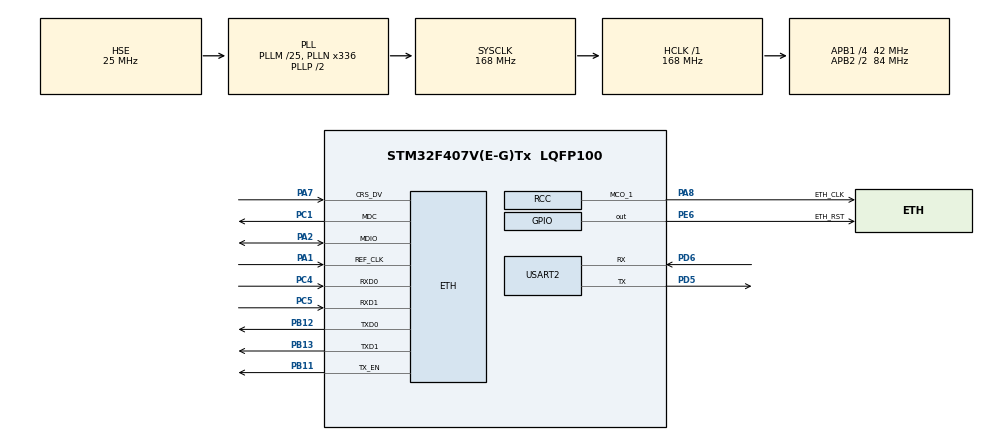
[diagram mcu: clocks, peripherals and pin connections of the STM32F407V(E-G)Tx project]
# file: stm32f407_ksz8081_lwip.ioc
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ETH.MACAddr=00\:80\:E1\:00\:00\:01
ETH.MediaInterface=HAL_ETH_RMII_MODE
LWIP.BSP.number=1
LWIP.CHECKSUM_BY_HARDWARE=0
LWIP.CHECKSUM_CHECK_IP=1
LWIP.CHECKSUM_CHECK_TCP=1
LWIP.CHECKSUM_CHECK_UDP=1
LWIP.CHECKSUM_GEN_ICMP=0
LWIP.CHECKSUM_GEN_IP=1
LWIP.CHECKSUM_GEN_TCP=1
LWIP.CHECKSUM_GEN_UDP=1
LWIP.IP_ADDRESS=192.168.100.118
LWIP.LWIP_DHCP=0
LWIP.NETMASK_ADDRESS=255.255.255.000
LWIP.Version=v2.1.2_Cube
LWIP0.BSP.STBoard=false
LWIP0.BSP.api=BSP_COMPONENT_DRIVER
LWIP0.BSP.component=LAN8742
LWIP0.BSP.i2caddr=0
LWIP0.BSP.instance=LAN8742
LWIP0.BSP.name=Driver_PHY
LWIP0.BSP.semaphore=S_LAN8742
LWIP0.BSP.solution=LAN8742
Mcu.Family=STM32F4
Mcu.Name=STM32F407V(E-G)Tx
Mcu.Package=LQFP100
NVIC.PriorityGroup=NVIC_PRIORITYGROUP_4
NVIC.USART2_IRQn=true\:0\:0\:false\:false\:true\:true\:true\:true
PA1.Mode=RMII
PA1.Signal=ETH_REF_CLK
PA2.Mode=RMII
PA2.Signal=ETH_MDIO
PA7.Mode=RMII
PA7.Signal=ETH_CRS_DV
PA8.GPIO_Label=ETH_CLK
PA8.Mode=Clock-out-1
PA8.Signal=RCC_MCO_1
PB11.Mode=RMII
PB11.Signal=ETH_TX_EN
PB12.Mode=RMII
PB12.Signal=ETH_TXD0
PB13.Mode=RMII
PB13.Signal=ETH_TXD1
PC1.Mode=RMII
PC1.Signal=ETH_MDC
PC4.Mode=RMII
PC4.Signal=ETH_RXD0
PC5.Mode=RMII
PC5.Signal=ETH_RXD1
PD5.Mode=Asynchronous
PD5.Signal=USART2_TX
PD6.Mode=Asynchronous
PD6.Signal=USART2_RX
PE6.GPIO_Label=ETH_RST
PE6.Signal=GPIO_Output
PH0-OSC_IN.Mode=HSE-External-Oscillator
PH0-OSC_IN.Signal=RCC_OSC_IN
PH1-OSC_OUT.Mode=HSE-External-Oscillator
PH1-OSC_OUT.Signal=RCC_OSC_OUT
ProjectManager.HeapSize=0x200
ProjectManager.StackSize=0x400
ProjectManager.TargetToolchain=STM32CubeIDE
RCC.48MHZClocksFreq_Value=84000000
RCC.AHBFreq_Value=168000000
RCC.APB1CLKDivider=RCC_HCLK_DIV4
RCC.APB1Freq_Value=42000000
RCC.APB1TimFreq_Value=84000000
RCC.APB2CLKDivider=RCC_HCLK_DIV2
RCC.APB2Freq_Value=84000000
RCC.APB2TimFreq_Value=168000000
RCC.CortexFreq_Value=168000000
RCC.HCLKFreq_Value=168000000
RCC.HSE_VALUE=25000000
RCC.HSI_VALUE=16000000
RCC.LSE_VALUE=32768
RCC.PLLM=25
RCC.PLLN=336
RCC.PLLSourceVirtual=RCC_PLLSOURCE_HSE
RCC.RCC_MCO1Source=RCC_MCO1SOURCE_HSE
RCC.SYSCLKFreq_VALUE=168000000
RCC.SYSCLKSource=RCC_SYSCLKSOURCE_PLLCLK
RCC.VCOOutputFreq_Value=336000000
USART2.VirtualMode=VM_ASYNC
VP_LWIP_VS_Enabled.Mode=Enabled
board=custom

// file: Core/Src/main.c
/* USER CODE BEGIN Header */
/**
  ******************************************************************************
  * @file           : main.c
  * @brief          : Main program body
  ******************************************************************************
  * @attention
  *
  * Copyright (c) 2022 STMicroelectronics.
  * All rights reserved.
  *
  * This software is licensed under terms that can be found in the LICENSE file
  * in the root directory of this software component.
  * If no LICENSE file comes with this software, it is provided AS-IS.
  *
  ******************************************************************************
  */
/* USER CODE END Header */
#include "main.h"
#include "lwip.h"

/* USER CODE BEGIN PTD */
#ifdef __GNUC__
/* With GCC/RAISONANCE, small printf (option LD Linker->Libraries->Small printf
 set to 'Yes') calls __io_putchar() */
#define PUTCHAR_PROTOTYPE int __io_putchar(int ch)
#else
#define PUTCHAR_PROTOTYPE int fputc(int ch, FILE *f)
#endif /* __GNUC__ */

/* USER CODE END PTD */

 UART_HandleTypeDef huart2;

void SystemClock_Config(void);
static void MX_GPIO_Init(void);
static void MX_USART2_UART_Init(void);

int main(void)
{

  /* MCU Configuration--------------------------------------------------------*/

  /* Reset of all peripherals, Initializes the Flash interface and the Systick. */
  HAL_Init();

  /* Configure the system clock */
  SystemClock_Config();

  /* Initialize all configured peripherals */
  MX_GPIO_Init();
  MX_USART2_UART_Init();
  MX_LWIP_Init();

  /* Infinite loop */
  while (1)
  {

    /* USER CODE BEGIN 3 */
	  MX_LWIP_Process();
  }
  /* USER CODE END 3 */
}

void SystemClock_Config(void)
{
  RCC_OscInitTypeDef RCC_OscInitStruct = {0};
  RCC_ClkInitTypeDef RCC_ClkInitStruct = {0};

  /** Configure the main internal regulator output voltage
  */
  __HAL_RCC_PWR_CLK_ENABLE();
  __HAL_PWR_VOLTAGESCALING_CONFIG(PWR_REGULATOR_VOLTAGE_SCALE1);

  /** Initializes the RCC Oscillators according to the specified parameters
  * in the RCC_OscInitTypeDef structure.
  */
  RCC_OscInitStruct.OscillatorType = RCC_OSCILLATORTYPE_HSE;
  RCC_OscInitStruct.HSEState = RCC_HSE_ON;
  RCC_OscInitStruct.PLL.PLLState = RCC_PLL_ON;
  RCC_OscInitStruct.PLL.PLLSource = RCC_PLLSOURCE_HSE;
  RCC_OscInitStruct.PLL.PLLM = 25;
  RCC_OscInitStruct.PLL.PLLN = 336;
  RCC_OscInitStruct.PLL.PLLP = RCC_PLLP_DIV2;
  RCC_OscInitStruct.PLL.PLLQ = 4;
  if (HAL_RCC_OscConfig(&RCC_OscInitStruct) != HAL_OK)
  {
    Error_Handler();
  }

  /** Initializes the CPU, AHB and APB buses clocks
  */
  RCC_ClkInitStruct.ClockType = RCC_CLOCKTYPE_HCLK|RCC_CLOCKTYPE_SYSCLK
                              |RCC_CLOCKTYPE_PCLK1|RCC_CLOCKTYPE_PCLK2;
  RCC_ClkInitStruct.SYSCLKSource = RCC_SYSCLKSOURCE_PLLCLK;
  RCC_ClkInitStruct.AHBCLKDivider = RCC_SYSCLK_DIV1;
  RCC_ClkInitStruct.APB1CLKDivider = RCC_HCLK_DIV4;
  RCC_ClkInitStruct.APB2CLKDivider = RCC_HCLK_DIV2;

  if (HAL_RCC_ClockConfig(&RCC_ClkInitStruct, FLASH_LATENCY_5) != HAL_OK)
  {
    Error_Handler();
  }
  HAL_RCC_MCOConfig(RCC_MCO1, RCC_MCO1SOURCE_HSE, RCC_MCODIV_1);
}

static void MX_USART2_UART_Init(void)
{

  huart2.Instance = USART2;
  huart2.Init.BaudRate = 115200;
  huart2.Init.WordLength = UART_WORDLENGTH_8B;
  huart2.Init.StopBits = UART_STOPBITS_1;
  huart2.Init.Parity = UART_PARITY_NONE;
  huart2.Init.Mode = UART_MODE_TX_RX;
  huart2.Init.HwFlowCtl = UART_HWCONTROL_NONE;
  huart2.Init.OverSampling = UART_OVERSAMPLING_16;
  if (HAL_UART_Init(&huart2) != HAL_OK)
  {
    Error_Handler();
  }

}

static void MX_GPIO_Init(void)
{
  GPIO_InitTypeDef GPIO_InitStruct = {0};

  /* GPIO Ports Clock Enable */
  __HAL_RCC_GPIOE_CLK_ENABLE();
  __HAL_RCC_GPIOH_CLK_ENABLE();
  __HAL_RCC_GPIOC_CLK_ENABLE();
  __HAL_RCC_GPIOA_CLK_ENABLE();
  __HAL_RCC_GPIOB_CLK_ENABLE();
  __HAL_RCC_GPIOD_CLK_ENABLE();

  /*Configure GPIO pin Output Level */
  HAL_GPIO_WritePin(ETH_RST_GPIO_Port, ETH_RST_Pin, GPIO_PIN_RESET);

  /*Configure GPIO pin : ETH_RST_Pin */
  GPIO_InitStruct.Pin = ETH_RST_Pin;
  GPIO_InitStruct.Mode = GPIO_MODE_OUTPUT_PP;
  GPIO_InitStruct.Pull = GPIO_NOPULL;
  GPIO_InitStruct.Speed = GPIO_SPEED_FREQ_LOW;
  HAL_GPIO_Init(ETH_RST_GPIO_Port, &GPIO_InitStruct);

  /*Configure GPIO pin : ETH_CLK_Pin */
  GPIO_InitStruct.Pin = ETH_CLK_Pin;
  GPIO_InitStruct.Mode = GPIO_MODE_AF_PP;
  GPIO_InitStruct.Pull = GPIO_NOPULL;
  GPIO_InitStruct.Speed = GPIO_SPEED_FREQ_LOW;
  GPIO_InitStruct.Alternate = GPIO_AF0_MCO;
  HAL_GPIO_Init(ETH_CLK_GPIO_Port, &GPIO_InitStruct);

}

/* USER CODE BEGIN 4 */
PUTCHAR_PROTOTYPE {
	/* Place your implementation of fputc here */
	/* e.g. write a character to the USART */
	// HAL_UART_Transmit(&huart2, (uint8_t *)&ch, 1, 100);
	while (!(USART2->SR & USART_SR_TXE))
		;
	USART2->DR = ch;

	return ch;
}
/* USER CODE END 4 */

void Error_Handler(void)
{
  __disable_irq();
  while (1)
  {
  }
}
